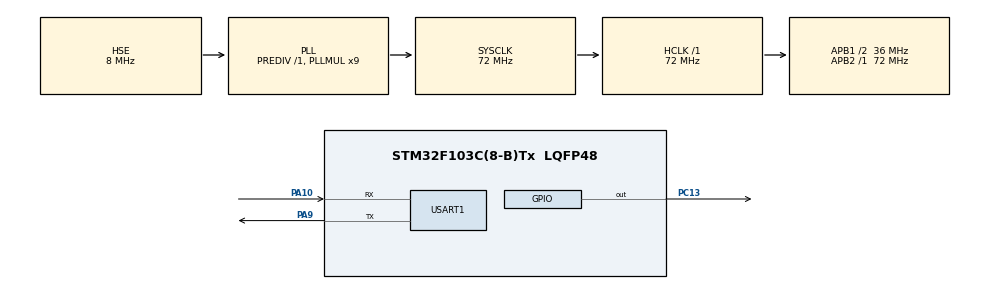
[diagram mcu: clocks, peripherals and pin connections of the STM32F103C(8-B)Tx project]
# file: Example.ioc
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FREERTOS.Tasks01=defaultTask,0,128,StartDefaultTask,Default,NULL,Dynamic,NULL,NULL;LED_fast,0,128,StartLED_fast,Default,NULL,Dynamic,NULL,NULL;LED_slow,-2,128,StartLED_slow,Default,NULL,Dynamic,NULL,NULL
FREERTOS.configMAX_PRIORITIES=5
FREERTOS.configTOTAL_HEAP_SIZE=8192
Mcu.Family=STM32F1
Mcu.Name=STM32F103C(8-B)Tx
Mcu.Package=LQFP48
NVIC.PriorityGroup=NVIC_PRIORITYGROUP_4
NVIC.TIM2_IRQn=true\:15\:0\:false\:false\:true\:false\:false\:true\:true
NVIC.TimeBase=TIM2_IRQn
NVIC.TimeBaseIP=TIM2
PA10.Mode=Asynchronous
PA10.Signal=USART1_RX
PA9.Mode=Asynchronous
PA9.Signal=USART1_TX
PC13-TAMPER-RTC.Signal=GPIO_Output
PD0-OSC_IN.Mode=HSE-External-Oscillator
PD0-OSC_IN.Signal=RCC_OSC_IN
PD1-OSC_OUT.Mode=HSE-External-Oscillator
PD1-OSC_OUT.Signal=RCC_OSC_OUT
ProjectManager.HeapSize=0x200
ProjectManager.StackSize=0x400
ProjectManager.TargetToolchain=Makefile
RCC.AHBFreq_Value=72000000
RCC.APB1CLKDivider=RCC_HCLK_DIV2
RCC.APB1Freq_Value=36000000
RCC.APB1TimFreq_Value=72000000
RCC.APB2Freq_Value=72000000
RCC.APB2TimFreq_Value=72000000
RCC.HCLKFreq_Value=72000000
RCC.PLLMUL=RCC_PLL_MUL9
RCC.PLLSourceVirtual=RCC_PLLSOURCE_HSE
RCC.SYSCLKFreq_VALUE=72000000
RCC.SYSCLKSource=RCC_SYSCLKSOURCE_PLLCLK
RCC.USBFreq_Value=72000000
USART1.VirtualMode=VM_ASYNC
VP_FREERTOS_VS_CMSIS_V1.Mode=CMSIS_V1
VP_SYS_VS_ND.Mode=No_Debug
VP_SYS_VS_tim2.Mode=TIM2
board=custom

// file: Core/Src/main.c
/* USER CODE BEGIN Header */
/**
  ******************************************************************************
  * @file           : main.c
  * @brief          : Main program body
  ******************************************************************************
  * @attention
  *
  * Copyright (c) 2026 STMicroelectronics.
  * All rights reserved.
  *
  * This software is licensed under terms that can be found in the LICENSE file
  * in the root directory of this software component.
  * If no LICENSE file comes with this software, it is provided AS-IS.
  *
  ******************************************************************************
  */
/* USER CODE END Header */
#include "main.h"
#include "cmsis_os.h"
#include "usart.h"
#include "gpio.h"

void SystemClock_Config(void);
void MX_FREERTOS_Init(void);

int main(void)
{

  /* MCU Configuration--------------------------------------------------------*/

  /* Reset of all peripherals, Initializes the Flash interface and the Systick. */
  HAL_Init();

  /* Configure the system clock */
  SystemClock_Config();

  /* Initialize all configured peripherals */
  MX_GPIO_Init();
  MX_USART1_UART_Init();

  /* Call init function for freertos objects (in cmsis_os2.c) */
  MX_FREERTOS_Init();

  /* Start scheduler */
  osKernelStart();

  /* We should never get here as control is now taken by the scheduler */

  /* Infinite loop */
  while (1)
  {

  }
}

void SystemClock_Config(void)
{
  RCC_OscInitTypeDef RCC_OscInitStruct = {0};
  RCC_ClkInitTypeDef RCC_ClkInitStruct = {0};

  /** Initializes the RCC Oscillators according to the specified parameters
  * in the RCC_OscInitTypeDef structure.
  */
  RCC_OscInitStruct.OscillatorType = RCC_OSCILLATORTYPE_HSE;
  RCC_OscInitStruct.HSEState = RCC_HSE_ON;
  RCC_OscInitStruct.HSEPredivValue = RCC_HSE_PREDIV_DIV1;
  RCC_OscInitStruct.HSIState = RCC_HSI_ON;
  RCC_OscInitStruct.PLL.PLLState = RCC_PLL_ON;
  RCC_OscInitStruct.PLL.PLLSource = RCC_PLLSOURCE_HSE;
  RCC_OscInitStruct.PLL.PLLMUL = RCC_PLL_MUL9;
  if (HAL_RCC_OscConfig(&RCC_OscInitStruct) != HAL_OK)
  {
    Error_Handler();
  }

  /** Initializes the CPU, AHB and APB buses clocks
  */
  RCC_ClkInitStruct.ClockType = RCC_CLOCKTYPE_HCLK|RCC_CLOCKTYPE_SYSCLK
                              |RCC_CLOCKTYPE_PCLK1|RCC_CLOCKTYPE_PCLK2;
  RCC_ClkInitStruct.SYSCLKSource = RCC_SYSCLKSOURCE_PLLCLK;
  RCC_ClkInitStruct.AHBCLKDivider = RCC_SYSCLK_DIV1;
  RCC_ClkInitStruct.APB1CLKDivider = RCC_HCLK_DIV2;
  RCC_ClkInitStruct.APB2CLKDivider = RCC_HCLK_DIV1;

  if (HAL_RCC_ClockConfig(&RCC_ClkInitStruct, FLASH_LATENCY_2) != HAL_OK)
  {
    Error_Handler();
  }
}

void HAL_TIM_PeriodElapsedCallback(TIM_HandleTypeDef *htim)
{
  if (htim->Instance == TIM2)
  {
    HAL_IncTick();
  }
}

void Error_Handler(void)
{
  __disable_irq();
  while (1)
  {
  }
}

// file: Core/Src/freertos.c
/* USER CODE BEGIN Header */
/**
  ******************************************************************************
  * File Name          : freertos.c
  * Description        : Code for freertos applications
  ******************************************************************************
  * @attention
  *
  * Copyright (c) 2026 STMicroelectronics.
  * All rights reserved.
  *
  * This software is licensed under terms that can be found in the LICENSE file
  * in the root directory of this software component.
  * If no LICENSE file comes with this software, it is provided AS-IS.
  *
  ******************************************************************************
  */
/* USER CODE END Header */

#include "FreeRTOS.h"
#include "task.h"
#include "main.h"
#include "cmsis_os.h"

osThreadId defaultTaskHandle;
osThreadId LED_fastHandle;
osThreadId LED_slowHandle;

void StartDefaultTask(void const * argument);
void StartLED_fast(void const * argument);
void StartLED_slow(void const * argument);

void MX_FREERTOS_Init(void); /* (MISRA C 2004 rule 8.1) */

/* GetIdleTaskMemory prototype (linked to static allocation support) */
void vApplicationGetIdleTaskMemory( StaticTask_t **ppxIdleTaskTCBBuffer, StackType_t **ppxIdleTaskStackBuffer, uint32_t *pulIdleTaskStackSize );

/* USER CODE BEGIN GET_IDLE_TASK_MEMORY */
static StaticTask_t xIdleTaskTCBBuffer;
static StackType_t xIdleStack[configMINIMAL_STACK_SIZE];

void vApplicationGetIdleTaskMemory( StaticTask_t **ppxIdleTaskTCBBuffer, StackType_t **ppxIdleTaskStackBuffer, uint32_t *pulIdleTaskStackSize )
{
  *ppxIdleTaskTCBBuffer = &xIdleTaskTCBBuffer;
  *ppxIdleTaskStackBuffer = &xIdleStack[0];
  *pulIdleTaskStackSize = configMINIMAL_STACK_SIZE;
  /* place for user code */
}
/* USER CODE END GET_IDLE_TASK_MEMORY */

void MX_FREERTOS_Init(void) {

  /* Create the thread(s) */
  /* definition and creation of defaultTask */
  osThreadDef(defaultTask, StartDefaultTask, osPriorityNormal, 0, 128);
  defaultTaskHandle = osThreadCreate(osThread(defaultTask), NULL);

  /* definition and creation of LED_fast */
  osThreadDef(LED_fast, StartLED_fast, osPriorityNormal, 0, 128);
  LED_fastHandle = osThreadCreate(osThread(LED_fast), NULL);

  /* definition and creation of LED_slow */
  osThreadDef(LED_slow, StartLED_slow, osPriorityLow, 0, 128);
  LED_slowHandle = osThreadCreate(osThread(LED_slow), NULL);

}

void StartDefaultTask(void const * argument)
{
  for(;;)
  {
    osDelay(1);
  }
}

void StartLED_fast(void const * argument)
{
  /* USER CODE BEGIN StartLED_fast */
  /* Infinite loop */
  for(;;)
  {
    HAL_GPIO_TogglePin(GPIOC, GPIO_PIN_13);
    osDelay(100);
  }
  /* USER CODE END StartLED_fast */
}

void StartLED_slow(void const * argument)
{
  /* USER CODE BEGIN StartLED_slow */
  /* Infinite loop */
  for(;;)
  {
    HAL_GPIO_TogglePin(GPIOC, GPIO_PIN_13);
    osDelay(500);
  }
  /* USER CODE END StartLED_slow */
}
